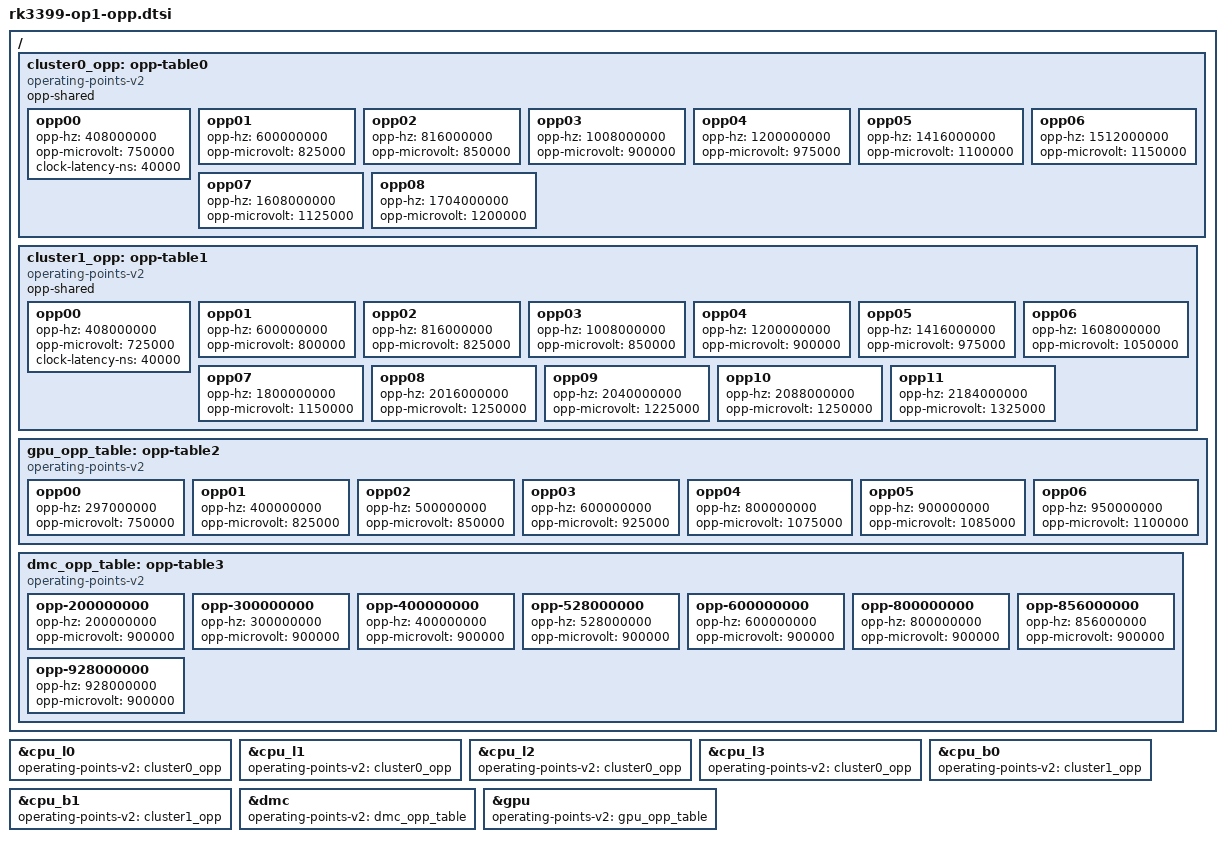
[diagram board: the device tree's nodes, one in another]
// SPDX-License-Identifier: (GPL-2.0+ OR MIT)
/*
 * Copyright (c) 2016-2017 Fuzhou Rockchip Electronics Co., Ltd
 */

/ {
	cluster0_opp: opp-table0 {
		compatible = "operating-points-v2";
		opp-shared;

		opp00 {
			opp-hz = /bits/ 64 <408000000>;
			opp-microvolt = <750000>;
			clock-latency-ns = <40000>;
		};
		opp01 {
			opp-hz = /bits/ 64 <600000000>;
			opp-microvolt = <825000>;
		};
		opp02 {
			opp-hz = /bits/ 64 <816000000>;
			opp-microvolt = <850000>;
		};
		opp03 {
			opp-hz = /bits/ 64 <1008000000>;
			opp-microvolt = <900000>;
		};
		opp04 {
			opp-hz = /bits/ 64 <1200000000>;
			opp-microvolt = <975000>;
		};
		opp05 {
			opp-hz = /bits/ 64 <1416000000>;
			opp-microvolt = <1100000>;
		};
		opp06 {
			opp-hz = /bits/ 64 <1512000000>;
			opp-microvolt = <1150000>;
		};
        	opp07 {
           		opp-hz = /bits/ 64 <1608000000>;
            		opp-microvolt = <1125000>;
        	};
        	opp08 {
            		opp-hz = /bits/ 64 <1704000000>;
            		opp-microvolt = <1200000>;
        	};	
	};

	cluster1_opp: opp-table1 {
		compatible = "operating-points-v2";
		opp-shared;

		opp00 {
			opp-hz = /bits/ 64 <408000000>;
			opp-microvolt = <725000>;
			clock-latency-ns = <40000>;
		};
		opp01 {
			opp-hz = /bits/ 64 <600000000>;
			opp-microvolt = <800000>;
		};
		opp02 {
			opp-hz = /bits/ 64 <816000000>;
			opp-microvolt = <825000>;
		};
		opp03 {
			opp-hz = /bits/ 64 <1008000000>;
			opp-microvolt = <850000>;
		};
		opp04 {
			opp-hz = /bits/ 64 <1200000000>;
			opp-microvolt = <900000>;
		};
		opp05 {
			opp-hz = /bits/ 64 <1416000000>;
			opp-microvolt = <975000>;
		};
		opp06 {
			opp-hz = /bits/ 64 <1608000000>;
			opp-microvolt = <1050000>;
		};
		opp07 {
			opp-hz = /bits/ 64 <1800000000>;
			opp-microvolt = <1150000>;
		};
		opp08 {
			opp-hz = /bits/ 64 <2016000000>;
			opp-microvolt = <1250000>;
		};
		opp09 {
            		opp-hz = /bits/ 64 <2040000000>;
            		opp-microvolt = <1225000>;
        	};
		opp10 {
            		opp-hz = /bits/ 64 <2088000000>;
            		opp-microvolt = <1250000>;
        	};
		opp11 {
            		opp-hz = /bits/ 64 <2184000000>;
            		opp-microvolt = <1325000>;
        	};		
	};

	gpu_opp_table: opp-table2 {
		compatible = "operating-points-v2";

		opp00 {
			opp-hz = /bits/ 64 <297000000>;
			opp-microvolt = <750000>;
		};
		opp01 {
			opp-hz = /bits/ 64 <400000000>;
			opp-microvolt = <825000>;
		};
		opp02 {
			opp-hz = /bits/ 64 <500000000>;
			opp-microvolt = <850000>;
		};
		opp03 {
			opp-hz = /bits/ 64 <600000000>;
			opp-microvolt = <925000>;
		};
		opp04 {
			opp-hz = /bits/ 64 <800000000>;
			opp-microvolt = <1075000>;
		};
        	opp05 {
         		opp-hz = /bits/ 64 <900000000>;
            		opp-microvolt = <1085000>;
        	};
        	opp06 {
         		opp-hz = /bits/ 64 <950000000>;
            		opp-microvolt = <1100000>;
        	};        			
	};
	
	dmc_opp_table: opp-table3 {
		compatible = "operating-points-v2";

		opp-200000000 {
			opp-hz = /bits/ 64 <200000000>;
			opp-microvolt = <900000>;
		};
		opp-300000000 {
			opp-hz = /bits/ 64 <300000000>;
			opp-microvolt = <900000>;
		};
		opp-400000000 {
			opp-hz = /bits/ 64 <400000000>;
			opp-microvolt = <900000>;
		};
		opp-528000000 {
			opp-hz = /bits/ 64 <528000000>;
			opp-microvolt = <900000>;
		};
		opp-600000000 {
			opp-hz = /bits/ 64 <600000000>;
			opp-microvolt = <900000>;
		};
		opp-800000000 {
			opp-hz = /bits/ 64 <800000000>;
			opp-microvolt = <900000>;
		};
		opp-856000000 {
			opp-hz = /bits/ 64 <856000000>;
			opp-microvolt = <900000>;
		};
		opp-928000000 {
			opp-hz = /bits/ 64 <928000000>;
			opp-microvolt = <900000>;
		};			
	};	
};

&cpu_l0 {
	operating-points-v2 = <&cluster0_opp>;
};

&cpu_l1 {
	operating-points-v2 = <&cluster0_opp>;
};

&cpu_l2 {
	operating-points-v2 = <&cluster0_opp>;
};

&cpu_l3 {
	operating-points-v2 = <&cluster0_opp>;
};

&cpu_b0 {
	operating-points-v2 = <&cluster1_opp>;
};

&cpu_b1 {
	operating-points-v2 = <&cluster1_opp>;
};

&dmc {
	operating-points-v2 = <&dmc_opp_table>;
};

&gpu {
	operating-points-v2 = <&gpu_opp_table>;
};
